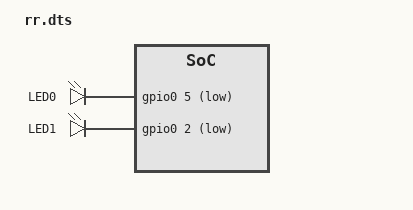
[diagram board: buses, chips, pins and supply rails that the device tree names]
/*
 * Copyright (c) 2021 Yonatan Schachter
 *
 * SPDX-License-Identifier: Apache-2.0
 */

/dts-v1/;

#include "rr-common.dtsi"

/ {
	leds {
		compatible = "gpio-leds";
		led0: led_0 {
			gpios = <&gpio0 5 GPIO_ACTIVE_LOW>;
			label = "LED0";
		};
		led1: led_1 {
                        gpios = <&gpio0 2 GPIO_ACTIVE_LOW>;
                        label = "LED1";
                };
	};

	pwm_leds {
		compatible = "pwm-leds";
		status = "disabled";
		pwm_led0: pwm_led_0 {
			pwms = <&pwm 9 PWM_MSEC(20) PWM_POLARITY_NORMAL>;
			label = "PWM_LED";
		};
	};

	aliases {
		led0 = &led0;
		led1 = &led1;
		pwm-led0 = &pwm_led0;
	};
};
